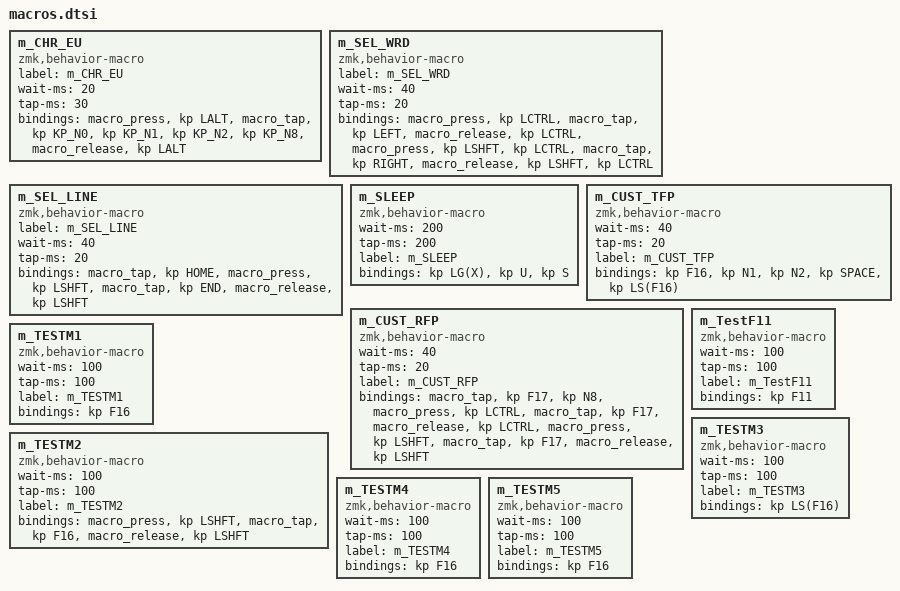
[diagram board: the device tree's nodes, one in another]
/* € - but clunky; seems some newer macros send Unicode better - need to search */
m_CHR_EU: m_CHR_EU{
    compatible = "zmk,behavior-macro";
    label = "m_CHR_EU";
    wait-ms = <20>;
    tap-ms = <30>;
    #binding-cells = <0>;
    bindings
        = <&macro_press   &kp LALT>
        , <&macro_tap     &kp KP_N0 &kp KP_N1 &kp KP_N2 &kp KP_N8>
        , <&macro_release &kp LALT>
        ;
};

/* SELECT WORD: Ctrl+LEFT, Ctrl+Shift+RIGHT */
m_SEL_WRD: m_SEL_WRD{
    compatible = "zmk,behavior-macro";
    label = "m_SEL_WRD";
    wait-ms = <40>;  /* 40,40 seems more reliable than 30,20 or faster */
    tap-ms = <20>;
    #binding-cells = <0>;
    bindings
        = <&macro_press &kp LCTRL>
        , <&macro_tap &kp LEFT>
        , <&macro_release &kp LCTRL>
        , <&macro_press &kp LSHFT &kp LCTRL>
        , <&macro_tap &kp RIGHT>
        , <&macro_release &kp LSHFT &kp LCTRL>
        ;
};

/* SELECT LINE: Home, Shift+End */
m_SEL_LINE: m_SEL_LINE{
    compatible = "zmk,behavior-macro";
    label = "m_SEL_LINE";
    wait-ms = <40>;
    tap-ms = <20>;
    #binding-cells = <0>;
    bindings
        = <&macro_tap &kp HOME>
        , <&macro_press &kp LSHFT>
        , <&macro_tap &kp END>
        , <&macro_release &kp LSHFT>
        ;
};

/* WINDOWS SLEEP: Win+X, U, S    (because the k-sleep and c-sleep don't seem to work / see https://github.com/zmkfirmware/zmk/issues/1077) */
/* NOT working yet; maybe need more pausing or split the sends?? */
m_SLEEP: m_SLEEP {
    wait-ms = <200>;
    tap-ms = <200>;  /* trying longer */
    compatible = "zmk,behavior-macro";
    label = "m_SLEEP";
    #binding-cells = <0>;
    bindings = <&kp LG(X)>, <&kp U>, <&kp S>; /* try separated? */
};

/* CUST_TFP - certain keystrokes to automate that one app hard function */
m_CUST_TFP: m_CUST_TFP {
    wait-ms = <40>;
    tap-ms = <20>;
    compatible = "zmk,behavior-macro";
    label = "m_CUST_TFP";
    #binding-cells = <0>;
    bindings = <&kp F16>, <&kp N1>, <&kp N2>, <&kp SPACE>, <&kp LS(F16)>;
};

/* CUST_RFP - similar as above ... */
m_CUST_RFP: m_CUST_RFP {
    wait-ms = <40>;
    tap-ms = <20>;
    compatible = "zmk,behavior-macro";
    label = "m_CUST_RFP";
    #binding-cells = <0>;
    /*bindings = <&kp F17 &kp N8 &kp LC(F17) &kp LS(F17)>;   || only getting the numbers...*/
    bindings = <&macro_tap &kp F17 &kp N8>
             , <&macro_press &kp LCTRL>
             , <&macro_tap &kp F17>
             , <&macro_release &kp LCTRL>
             , <&macro_press &kp LSHFT>
             , <&macro_tap &kp F17>
             , <&macro_release &kp LSHFT>
             ;
};

/* simple F11 send works fine... A simple send F16 seems to do nothing... Is it the ≥F12 cases that's the issue? */
/* related to this option? https://github.com/zmkfirmware/zmk/issues/1460 ... ?  commented out this in 2 files (left, right): CONFIG_ZMK_HID_REPORT_TYPE_NKRO=y */
/* ******** YES YES ^^ commenting out this option then worked!  ********** */
m_TestF11: m_TestF11 {
    wait-ms = <100>;
    tap-ms = <100>;
    compatible = "zmk,behavior-macro";
    label = "m_TestF11";
    #binding-cells = <0>;
    bindings = <&kp F11>;
};


/* ************************************************** */
/* TEST macros to futz with settings in batches */
m_TESTM1: m_TESTM1 {
    wait-ms = <100>;
    tap-ms = <100>;
    compatible = "zmk,behavior-macro";
    label = "m_TESTM1";
    #binding-cells = <0>;
    bindings = <&kp F16>;
};

m_TESTM2: m_TESTM2 {
    wait-ms = <100>;
    tap-ms = <100>;
    compatible = "zmk,behavior-macro";
    label = "m_TESTM2";
    #binding-cells = <0>;
    bindings = <&macro_press &kp LSHFT>
             , <&macro_tap &kp F16>
             , <&macro_release &kp LSHFT>
             ;
};

m_TESTM3: m_TESTM3 {
    wait-ms = <100>;
    tap-ms = <100>;
    compatible = "zmk,behavior-macro";
    label = "m_TESTM3";
    #binding-cells = <0>;
    bindings = <&kp LS(F16)>;
};

m_TESTM4: m_TESTM4 {
    wait-ms = <100>;
    tap-ms = <100>;
    compatible = "zmk,behavior-macro";
    label = "m_TESTM4";
    #binding-cells = <0>;
    bindings = <&kp F16>;
};

m_TESTM5: m_TESTM5 {
    wait-ms = <100>;
    tap-ms = <100>;
    compatible = "zmk,behavior-macro";
    label = "m_TESTM5";
    #binding-cells = <0>;
    bindings = <&kp F16>;
};





/* ************************************************** */
/* see also EW Notes file */

/* ************************************************** */
/* try ZMK macro helper shortcut -- NOT WORKING with nested FN() calls -- come back to later? */
/*
ZMK_MACRO(m_TEST2
    wait-ms = <30>;
    tap-ms = <20>;
    bindings = <&kp A>, <&kp B>;
)
*/

